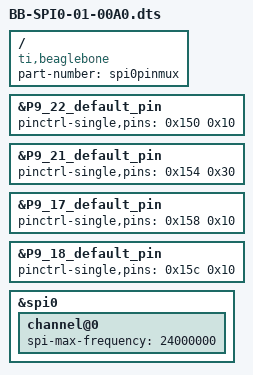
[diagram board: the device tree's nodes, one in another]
/dts-v1/;
/plugin/;

/ {
    compatible = "ti,beaglebone", "ti,beaglebone-black";
    /* identification */
    part-number = "spi0pinmux";

    fragment@0 {
	// spi_sclk 
        target = <&P9_22_default_pin>;
        __overlay__ {
		pinctrl-single,pins = <0x150 0x10>;
            };
    };
    fragment@1 {
	// spi_miso 
        target = <&P9_21_default_pin>;
        __overlay__ {
		pinctrl-single,pins = <0x154 0x30>;
            };
    };
    fragment@3 {
	// spi_cs0_
        target = <&P9_17_default_pin>;
        __overlay__ {
		pinctrl-single,pins = <0x158 0x10>;
            };
    };
    fragment@4 {
	// spi_D0 mosi
        target = <&P9_18_default_pin>;
        __overlay__ {
		pinctrl-single,pins = <0x15c 0x10>;
            };
    };
    fragment@5 {
	target = <&spi0>;
	__overlay__ {
		status = "okay";
		channel@0 {
			//compatible = "hehe,longvh";
			spi-max-frequency = <24000000>;
		};
	};
    };

};

